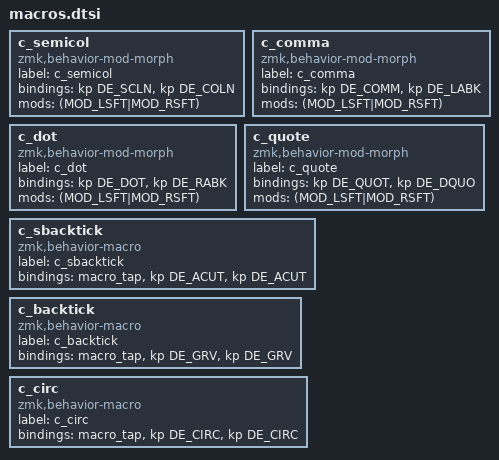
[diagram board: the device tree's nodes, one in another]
  c_semicol: c_semicol {
      label = "c_semicol";
      compatible = "zmk,behavior-mod-morph";
      #binding-cells = <0>;
      bindings = <&kp DE_SCLN>, <&kp DE_COLN>;
      mods = <(MOD_LSFT|MOD_RSFT)>;
  };
  c_comma: c_comma {
      label = "c_comma";
      compatible = "zmk,behavior-mod-morph";
      #binding-cells = <0>;
      bindings = <&kp DE_COMM>, <&kp DE_LABK>;
      mods = <(MOD_LSFT|MOD_RSFT)>;
  };
  c_dot: c_dot {
      label = "c_dot";
      compatible = "zmk,behavior-mod-morph";
      #binding-cells = <0>;
      bindings = <&kp DE_DOT>, <&kp DE_RABK>;
      mods = <(MOD_LSFT|MOD_RSFT)>;
  };
  c_quote: c_quote {
      label = "c_quote";
      compatible = "zmk,behavior-mod-morph";
      #binding-cells = <0>;
      bindings = <&kp DE_QUOT>, <&kp DE_DQUO>;
      mods = <(MOD_LSFT|MOD_RSFT)>;
  };
  c_sbacktick: c_sbacktick {
      label = "c_sbacktick";
      compatible = "zmk,behavior-macro";
      #binding-cells = <0>;
      bindings = <&macro_tap &kp DE_ACUT &kp DE_ACUT>;
  };
  c_backtick: c_backtick {
      label = "c_backtick";
      compatible = "zmk,behavior-macro";
      #binding-cells = <0>;
      bindings = <&macro_tap &kp DE_GRV &kp DE_GRV>;
  };
  c_circ: c_circ {
      label = "c_circ";
      compatible = "zmk,behavior-macro";
      #binding-cells = <0>;
      bindings = <&macro_tap &kp DE_CIRC &kp DE_CIRC>;
  };
